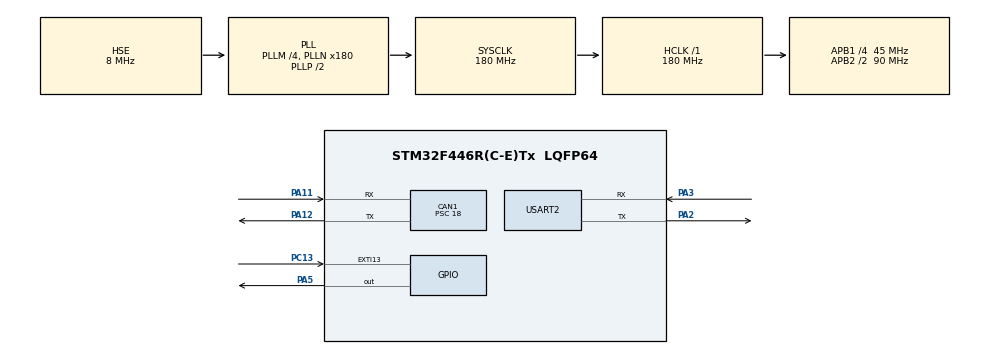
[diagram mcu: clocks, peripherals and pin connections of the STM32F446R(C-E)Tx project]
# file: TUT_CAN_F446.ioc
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CAN1.BS1=CAN_BS1_2TQ
CAN1.BS2=CAN_BS2_2TQ
CAN1.CalculateBaudRate=500000
CAN1.CalculateTimeBit=2000
CAN1.CalculateTimeQuantum=400.0
CAN1.Prescaler=18
Mcu.Family=STM32F4
Mcu.Name=STM32F446R(C-E)Tx
Mcu.Package=LQFP64
NVIC.CAN1_RX0_IRQn=true\:0\:0\:false\:false\:true\:true\:true\:true
NVIC.EXTI15_10_IRQn=true\:0\:0\:false\:false\:true\:true\:true\:true
NVIC.PriorityGroup=NVIC_PRIORITYGROUP_4
NVIC.USART2_IRQn=true\:0\:0\:false\:false\:true\:true\:true\:true
PA11.Mode=CAN_Activate
PA11.Signal=CAN1_RX
PA12.Mode=CAN_Activate
PA12.Signal=CAN1_TX
PA2.Mode=Asynchronous
PA2.Signal=USART2_TX
PA3.Mode=Asynchronous
PA3.Signal=USART2_RX
PA5.Signal=GPIO_Output
PC13.Signal=GPXTI13
PH0-OSC_IN.Mode=HSE-External-Oscillator
PH0-OSC_IN.Signal=RCC_OSC_IN
PH1-OSC_OUT.Mode=HSE-External-Oscillator
PH1-OSC_OUT.Signal=RCC_OSC_OUT
ProjectManager.HeapSize=0x200
ProjectManager.StackSize=0x400
ProjectManager.TargetToolchain=MDK-ARM V5.32
RCC.AHBFreq_Value=180000000
RCC.APB1CLKDivider=RCC_HCLK_DIV4
RCC.APB1Freq_Value=45000000
RCC.APB1TimFreq_Value=90000000
RCC.APB2CLKDivider=RCC_HCLK_DIV2
RCC.APB2Freq_Value=90000000
RCC.APB2TimFreq_Value=180000000
RCC.CortexFreq_Value=180000000
RCC.HCLKFreq_Value=180000000
RCC.HSE_VALUE=8000000
RCC.PLLM=4
RCC.PLLN=180
RCC.PLLSourceVirtual=RCC_PLLSOURCE_HSE
RCC.SYSCLKFreq_VALUE=180000000
RCC.SYSCLKSource=RCC_SYSCLKSOURCE_PLLCLK
RCC.USBFreq_Value=180000000
RCC.VCOOutputFreq_Value=360000000
USART2.VirtualMode=VM_ASYNC
board=custom

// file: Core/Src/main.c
#include "main.h"
#include <stdio.h>
#include <string.h>

CAN_HandleTypeDef hcan1;
UART_HandleTypeDef huart2;
CAN_TxHeaderTypeDef TxHeader;
CAN_RxHeaderTypeDef RxHeader;

void SystemClock_Config(void);
static void MX_GPIO_Init(void);
static void MX_CAN1_Init(void);
static void MX_USART2_UART_Init(void);

static volatile int node1 = 0, node2 = 0, node3 = 0, node4 = 0;
static volatile int flag_node1 = 0, flag_node2 = 0, flag_node3 = 0, flag_node4 = 0;

uint8_t tx_buff[]={0,1,2,3,4,5,6,7,8,9};
uint8_t rx_buff[24];

uint8_t TxData[8];
uint8_t RxData[8];
uint32_t TxMailbox;

int main(void)
{
  HAL_Init();
  SystemClock_Config();

  MX_GPIO_Init();
  MX_CAN1_Init();
  MX_USART2_UART_Init();

  HAL_UART_Receive_IT(&huart2, rx_buff, 24);
//  HAL_UART_Transmit_IT(&huart2, tx_buff, 10);

  HAL_CAN_Start(&hcan1);
  HAL_CAN_ActivateNotification(&hcan1, CAN_IT_RX_FIFO0_MSG_PENDING);

  while (1)
  {

  }

}

void SystemClock_Config(void)
{
  RCC_OscInitTypeDef RCC_OscInitStruct = {0};
  RCC_ClkInitTypeDef RCC_ClkInitStruct = {0};

  /** Configure the main internal regulator output voltage
  */
  __HAL_RCC_PWR_CLK_ENABLE();
  __HAL_PWR_VOLTAGESCALING_CONFIG(PWR_REGULATOR_VOLTAGE_SCALE1);
  /** Initializes the RCC Oscillators according to the specified parameters
  * in the RCC_OscInitTypeDef structure.
  */
  RCC_OscInitStruct.OscillatorType = RCC_OSCILLATORTYPE_HSE;
  RCC_OscInitStruct.HSEState = RCC_HSE_ON;
  RCC_OscInitStruct.PLL.PLLState = RCC_PLL_ON;
  RCC_OscInitStruct.PLL.PLLSource = RCC_PLLSOURCE_HSE;
  RCC_OscInitStruct.PLL.PLLM = 4;
  RCC_OscInitStruct.PLL.PLLN = 180;
  RCC_OscInitStruct.PLL.PLLP = RCC_PLLP_DIV2;
  RCC_OscInitStruct.PLL.PLLQ = 2;
  RCC_OscInitStruct.PLL.PLLR = 2;
  if (HAL_RCC_OscConfig(&RCC_OscInitStruct) != HAL_OK)
  {
    Error_Handler();
  }
  /** Activate the Over-Drive mode
  */
  if (HAL_PWREx_EnableOverDrive() != HAL_OK)
  {
    Error_Handler();
  }
  /** Initializes the CPU, AHB and APB buses clocks
  */
  RCC_ClkInitStruct.ClockType = RCC_CLOCKTYPE_HCLK|RCC_CLOCKTYPE_SYSCLK
                              |RCC_CLOCKTYPE_PCLK1|RCC_CLOCKTYPE_PCLK2;
  RCC_ClkInitStruct.SYSCLKSource = RCC_SYSCLKSOURCE_PLLCLK;
  RCC_ClkInitStruct.AHBCLKDivider = RCC_SYSCLK_DIV1;
  RCC_ClkInitStruct.APB1CLKDivider = RCC_HCLK_DIV4;
  RCC_ClkInitStruct.APB2CLKDivider = RCC_HCLK_DIV2;

  if (HAL_RCC_ClockConfig(&RCC_ClkInitStruct, FLASH_LATENCY_5) != HAL_OK)
  {
    Error_Handler();
  }
}

static void MX_CAN1_Init(void)
{

  hcan1.Instance = CAN1;
  hcan1.Init.Prescaler = 18;
  hcan1.Init.Mode = CAN_MODE_NORMAL;
  hcan1.Init.SyncJumpWidth = CAN_SJW_1TQ;
  hcan1.Init.TimeSeg1 = CAN_BS1_2TQ;
  hcan1.Init.TimeSeg2 = CAN_BS2_2TQ;
  hcan1.Init.TimeTriggeredMode = DISABLE;
  hcan1.Init.AutoBusOff = DISABLE;
  hcan1.Init.AutoWakeUp = DISABLE;
  hcan1.Init.AutoRetransmission = DISABLE;
  hcan1.Init.ReceiveFifoLocked = DISABLE;
  hcan1.Init.TransmitFifoPriority = DISABLE;
  if (HAL_CAN_Init(&hcan1) != HAL_OK)
  {
    Error_Handler();
  }

}

static void MX_USART2_UART_Init(void)
{

  huart2.Instance = USART2;
  huart2.Init.BaudRate = 115200;
  huart2.Init.WordLength = UART_WORDLENGTH_8B;
  huart2.Init.StopBits = UART_STOPBITS_1;
  huart2.Init.Parity = UART_PARITY_NONE;
  huart2.Init.Mode = UART_MODE_TX_RX;
  huart2.Init.HwFlowCtl = UART_HWCONTROL_NONE;
  huart2.Init.OverSampling = UART_OVERSAMPLING_16;
  if (HAL_UART_Init(&huart2) != HAL_OK)
  {
    Error_Handler();
  }

}

static void MX_GPIO_Init(void)
{
  GPIO_InitTypeDef GPIO_InitStruct = {0};

  /* GPIO Ports Clock Enable */
  __HAL_RCC_GPIOC_CLK_ENABLE();
  __HAL_RCC_GPIOH_CLK_ENABLE();
  __HAL_RCC_GPIOA_CLK_ENABLE();

  /*Configure GPIO pin Output Level */
  HAL_GPIO_WritePin(GPIOA, GPIO_PIN_5, GPIO_PIN_RESET);

  /*Configure GPIO pin : PC13 */
  GPIO_InitStruct.Pin = GPIO_PIN_13;
  GPIO_InitStruct.Mode = GPIO_MODE_IT_RISING;
  GPIO_InitStruct.Pull = GPIO_NOPULL;
  HAL_GPIO_Init(GPIOC, &GPIO_InitStruct);

  /*Configure GPIO pin : PA5 */
  GPIO_InitStruct.Pin = GPIO_PIN_5;
  GPIO_InitStruct.Mode = GPIO_MODE_OUTPUT_PP;
  GPIO_InitStruct.Pull = GPIO_NOPULL;
  GPIO_InitStruct.Speed = GPIO_SPEED_FREQ_LOW;
  HAL_GPIO_Init(GPIOA, &GPIO_InitStruct);

  /* EXTI interrupt init*/
  HAL_NVIC_SetPriority(EXTI15_10_IRQn, 0, 0);
  HAL_NVIC_EnableIRQ(EXTI15_10_IRQn);

}

void HAL_UART_RxCpltCallback(UART_HandleTypeDef *huart)
{
  HAL_UART_Receive_IT(&huart2, rx_buff, 24);
	if((sscanf((char*)rx_buff, "%da%db%dc%dd", &node1, &node2, &node3, &node4)) == 4)
	{
	TxHeader.DLC = 4;  // data length
  TxHeader.IDE = CAN_ID_STD;
  TxHeader.RTR = CAN_RTR_DATA;
  TxHeader.StdId = 0x002;  // ID

	TxData[0] = (uint8_t)node1;
	TxData[1] = (uint8_t)node2;
	TxData[2] = (uint8_t)node3;
	TxData[3] = (uint8_t)node4;

	HAL_CAN_AddTxMessage(&hcan1, &TxHeader, TxData, &TxMailbox);
	}

}

void HAL_CAN_RxFifo0MsgPendingCallback(CAN_HandleTypeDef *hcan)
{
	HAL_CAN_GetRxMessage(hcan, CAN_RX_FIFO0, &RxHeader, RxData);
	if (RxHeader.StdId == 0x001)
	{
		flag_node1 = 1;
	}
	else if(RxHeader.StdId == 0x002)
	{
		flag_node2 = 1;
	}
	else if(RxHeader.StdId == 0x003)
	{
		flag_node3 = 1;
	}
	else if(RxHeader.StdId == 0x004)
	{
		flag_node4 = 1;
	}

}

void HAL_UART_TxCpltCallback(UART_HandleTypeDef *huart)
{
  __NOP();//test if we reach this position
}

void Error_Handler(void)
{
  __disable_irq();
  while (1)
  {
  }
}

#ifdef  USE_FULL_ASSERT
/**
  * @brief  Reports the name of the source file and the source line number
  *         where the assert_param error has occurred.
  * @param  file: pointer to the source file name
  * @param  line: assert_param error line source number
  * @retval None
  */
void assert_failed(uint8_t *file, uint32_t line)
{
  /* USER CODE BEGIN 6 */
  // Check if the received character is 'h'
  if (huart->Instance == USART2 && huart->pRxBuffPtr[0] == 'h')
  {
    // Set the flag indicating 'h' has been received
    hReceived = 1;

    // Restart the UART receive process
    HAL_UART_Receive_IT(&huart2, (uint8_t *)huart2.pRxBuffPtr, 1);
  }
  /* USER CODE END 6 */
}
#endif /* USE_FULL_ASSERT */

/************************ (C) COPYRIGHT STMicroelectronics *****END OF FILE****/
